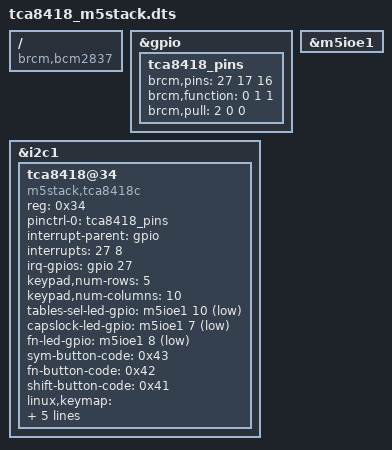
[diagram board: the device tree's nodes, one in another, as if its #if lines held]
/dts-v1/;
/plugin/;
// dtc -@ -I dts -O dtb -o m5stac_tca8418.dtbo  m5stac-tca8418.dts
/{
 
compatible = "brcm,bcm2837";
fragment@0 {
	target = <&gpio>;
	__overlay__ {
			tca8418_pins: tca8418_pins {
					brcm,pins = <27 17 16>;
					brcm,function = <0 1 1>;
					brcm,pull = <2 0 0>;
			};
	};
};
fragment@1 {
	target = <&m5ioe1>;
	__overlay__ {
		status = "okay";
	};
};
fragment@2 {
	target = <&i2c1>;
	__overlay__{
            tca8418@34 {
                compatible = "m5stack,tca8418c"; 
                reg = <0x34>;
                pinctrl-names = "default";
                pinctrl-0 = <&tca8418_pins>;
                interrupt-parent = <&gpio>;
                interrupts = <27 8>; /* Interrupt IO, low-level trigger */
                irq-gpios = <&gpio 27 0x00>;
                    
                keypad,num-rows = <5>;
                keypad,num-columns = <10>;

#if CONFIG_CARDPUTERO_V0_5
                tables-sel-led-gpio = <&m5ioe1 10 1>;
                capslock-led-gpio   = <&m5ioe1 7 1>;
                fn-led-gpio         = <&m5ioe1 8 1>;
                // tables-sel-led-mode    = <&m5ioe1 15>;
                // capslock-led-mode    = <&m5ioe1 16>;
                // fn-led-mode    = <&m5ioe1 17>;
#else
                tables-sel-led-gpio = <&m5ioe1 8 1>;
                capslock-led-gpio   = <&m5ioe1 7 1>;
#endif

                sym-button-code = <0x43>; 
                fn-button-code = <0x42>;  
                shift-button-code = <0x41>; 

                // switch-button-code = <73>; /* Switch button keycode */
                // interrupt-controller;
                /* row | column | key-code, for example: 04,08,0010 for the Q key */
                /* row | column | key-code, for example: 04,08,0010 => Q key */
                linux,keymap = <
                    0x04000001 /* row=0x04 col=0x00 keycode=0x0001  KEY_ESC        Esc */
                    0x0409000f /* row=0x04 col=0x09 keycode=0x000f  KEY_TAB        Tab */

                    0x04040002 /* row=0x04 col=0x04 keycode=0x0002  KEY_1          1 */
                    0x00000003 /* row=0x00 col=0x00 keycode=0x0003  KEY_2          2 */
                    0x00010004 /* row=0x00 col=0x01 keycode=0x0004  KEY_3          3 */
                    0x00020005 /* row=0x00 col=0x02 keycode=0x0005  KEY_4          4 */
                    0x00030006 /* row=0x00 col=0x03 keycode=0x0006  KEY_5          5 */
                    0x00040007 /* row=0x00 col=0x04 keycode=0x0007  KEY_6          6 */
                    0x00050008 /* row=0x00 col=0x05 keycode=0x0008  KEY_7          7 */
                    0x00060009 /* row=0x00 col=0x06 keycode=0x0009  KEY_8          8 */
                    0x0007000a /* row=0x00 col=0x07 keycode=0x000a  KEY_9          9 */
                    0x0008000b /* row=0x00 col=0x08 keycode=0x000b  KEY_0          0 */
                    0x0009000e /* row=0x00 col=0x09 keycode=0x000e  KEY_BACKSPACE  Backspace */

                    0x0403017f /* row=0x04 col=0x03 keycode=0x017f  KEY_CD  Sym function key */
                    0x01000010 /* row=0x01 col=0x00 keycode=0x0010  KEY_Q          Q */
                    0x01010011 /* row=0x01 col=0x01 keycode=0x0011  KEY_W          W */
                    0x01020012 /* row=0x01 col=0x02 keycode=0x0012  KEY_E          E */
                    0x01030013 /* row=0x01 col=0x03 keycode=0x0013  KEY_R          R */
                    0x01040014 /* row=0x01 col=0x04 keycode=0x0014  KEY_T          T */
                    0x01050015 /* row=0x01 col=0x05 keycode=0x0015  KEY_Y          Y */
                    0x01060016 /* row=0x01 col=0x06 keycode=0x0016  KEY_U          U */
                    0x01070017 /* row=0x01 col=0x07 keycode=0x0017  KEY_I          I */
                    0x01080018 /* row=0x01 col=0x08 keycode=0x0018  KEY_O          O */
                    0x01090019 /* row=0x01 col=0x09 keycode=0x0019  KEY_P          P */


                    0x0401002a /* row=0x04 col=0x01 keycode=0x002a  KEY_LEFTSHIFT    Left Shift */
                    0x0200001e /* row=0x02 col=0x00 keycode=0x001e  KEY_A          A */
                    0x0201001f /* row=0x02 col=0x01 keycode=0x001f  KEY_S          S */
                    0x02020020 /* row=0x02 col=0x02 keycode=0x0020  KEY_D          D */
                    0x02030021 /* row=0x02 col=0x03 keycode=0x0021  KEY_F          F */
                    0x02040022 /* row=0x02 col=0x04 keycode=0x0022  KEY_G          G */
                    0x02050023 /* row=0x02 col=0x05 keycode=0x0023  KEY_H          H */
                    0x02060024 /* row=0x02 col=0x06 keycode=0x0024  KEY_J          J */
                    0x02070025 /* row=0x02 col=0x07 keycode=0x0025  KEY_K          K */
                    0x02080026 /* row=0x02 col=0x08 keycode=0x0026  KEY_L          L */
                    0x0209001c /* row=0x02 col=0x09 keycode=0x001c  KEY_ENTER      Enter */

                    0x04020185 /* row=0x04 col=0x02 keycode=0x0185  KEY_DVD  Fn function key */
                    0x0300001d /* row=0x03 col=0x00 keycode=0x001d  KEY_LEFTCTRL   Left Ctrl */
                    0x03010038 /* row=0x03 col=0x01 keycode=0x0038  KEY_LEFTALT    Left Alt  */
                    0x0302002c /* row=0x03 col=0x02 keycode=0x002c  KEY_Z          Z */
                    0x0303002d /* row=0x03 col=0x03 keycode=0x002d  KEY_X          X */
                    0x0304002e /* row=0x03 col=0x04 keycode=0x002e  KEY_C          C */
                    0x0305002f /* row=0x03 col=0x05 keycode=0x002f  KEY_V          V */
                    0x03060030 /* row=0x03 col=0x06 keycode=0x0030  KEY_B          B */
                    0x03070031 /* row=0x03 col=0x07 keycode=0x0031  KEY_N          N */
                    0x03080032 /* row=0x03 col=0x08 keycode=0x0032  KEY_M          M */
                    0x03090039 /* row=0x03 col=0x09 keycode=0x0039  KEY_SPACE      Space */
                    >;
                /* row | column | key-code */
                linux,keymap1 = <
                    0x04000001 /* row=0x04 col=0x00 keycode=0x0001  KEY_ESC        Esc */
                    0x0409000f /* row=0x04 col=0x09 keycode=0x000f  KEY_TAB        Tab */


                    0x0404001a /* row=0x04 col=0x04 keycode=0x001a  KEY_LEFTBRACE          Left Brace */
                    0x0000001b /* row=0x00 col=0x00 keycode=0x001b  KEY_RIGHTBRACE         Right Brace */
                    0x00010027 /* row=0x00 col=0x01 keycode=0x0027  KEY_SEMICOLON          Semicolon */
                    0x00020028 /* row=0x00 col=0x02 keycode=0x0028  KEY_APOSTROPHE         Apostrophe */
                    0x00030029 /* row=0x00 col=0x03 keycode=0x0029  KEY_GRAVE              Grave */
                    0x0004002b /* row=0x00 col=0x04 keycode=0x002b  KEY_BACKSLASH          Backslash */
                    0x00050033 /* row=0x00 col=0x05 keycode=0x0033  KEY_COMMA              Comma */
                    0x00060034 /* row=0x00 col=0x06 keycode=0x0034  KEY_DOT                Dot */
                    0x00070035 /* row=0x00 col=0x07 keycode=0x0035  KEY_SLASH              Slash */
                    0x0008005e /* row=0x00 col=0x08 keycode=0x005e  KEY_MUHENKAN           Muhenkan */
                    0x0009000e /* row=0x00 col=0x09 keycode=0x000e  KEY_BACKSPACE    Backspace */

                    0x0403017f /* row=0x04 col=0x03 keycode=0x017f  KEY_CD  Sym function key */
                    0x01000037 /* row=0x01 col=0x00 keycode=0x0037  KEY_KPASTERISK         Keypad Asterisk */
                    0x01010045 /* row=0x01 col=0x01 keycode=0x0045  KEY_NUMLOCK            Num Lock */
                    0x01020046 /* row=0x01 col=0x02 keycode=0x0046  KEY_SCROLLLOCK         Scroll Lock */
                    0x01030047 /* row=0x01 col=0x03 keycode=0x0047  KEY_KP7                Keypad 7 */
                    0x01040048 /* row=0x01 col=0x04 keycode=0x0048  KEY_KP8                Keypad 8 */
                    0x01050049 /* row=0x01 col=0x05 keycode=0x0049  KEY_KP9                Keypad 9 */
                    0x0106004a /* row=0x01 col=0x06 keycode=0x004a  KEY_KPMINUS            Keypad Minus */
                    0x0107004b /* row=0x01 col=0x07 keycode=0x004b  KEY_KP4                Keypad 4 */
                    0x0108004c /* row=0x01 col=0x08 keycode=0x004c  KEY_KP5                Keypad 5 */
                    0x0109004d /* row=0x01 col=0x09 keycode=0x004d  KEY_KP6                Keypad 6 */


                    0x0401004e /* row=0x04 col=0x01 keycode=0x004e  KEY_KPPLUS             Keypad Plus */
                    0x0200004f /* row=0x02 col=0x00 keycode=0x004f  KEY_KP1                Keypad 1 */
                    0x02010050 /* row=0x02 col=0x01 keycode=0x0050  KEY_KP2                Keypad 2 */
                    0x02020051 /* row=0x02 col=0x02 keycode=0x0051  KEY_KP3                Keypad 3 */
                    0x02030000 /* row=0x02 col=0x03 keycode=0x0000  KEY_RESERVED     F disabled */
                    0x02040052 /* row=0x02 col=0x04 keycode=0x0052  KEY_KP0                Keypad 0 */
                    0x02050053 /* row=0x02 col=0x05 keycode=0x0053  KEY_KPDOT              Keypad Dot */
                    0x02060055 /* row=0x02 col=0x06 keycode=0x0055  KEY_ZENKAKUHANKAKU     Zenkaku/Hankaku */
                    0x02070056 /* row=0x02 col=0x07 keycode=0x0056  KEY_102ND              102nd */
                    0x02080059 /* row=0x02 col=0x08 keycode=0x0059  KEY_RO                 Ro */
                    0x0209001c /* row=0x02 col=0x09 keycode=0x001c  KEY_ENTER        Enter */

                    0x04020185 /* row=0x04 col=0x02 keycode=0x0185  KEY_DVD  Fn function key */
                    0x0300001d /* row=0x03 col=0x00 keycode=0x001d  KEY_LEFTCTRL   Left Ctrl */
                    0x03010038 /* row=0x03 col=0x01 keycode=0x0038  KEY_LEFTALT    Left Alt  */
                    0x03020000 /* row=0x03 col=0x02 keycode=0x0000  KEY_RESERVED     Z disabled */
                    0x03030000 /* row=0x03 col=0x03 keycode=0x0000  KEY_RESERVED     X disabled */
                    0x03040000 /* row=0x03 col=0x04 keycode=0x0000  KEY_RESERVED     C disabled */
                    0x0305005a /* row=0x03 col=0x05 keycode=0x005a  KEY_KATAKANA           Katakana */
                    0x0306005b /* row=0x03 col=0x06 keycode=0x005b  KEY_HIRAGANA           Hiragana */
                    0x0307005c /* row=0x03 col=0x07 keycode=0x005c  KEY_HENKAN             Henkan */
                    0x0308005d /* row=0x03 col=0x08 keycode=0x005d  KEY_KATAKANAHIRAGANA   Katakana/Hiragana */
                    0x03090039 /* row=0x03 col=0x09 keycode=0x0039  KEY_SPACE        Space */
                    >;
                linux,keymap2 = <
                    0x04000001 /* row=0x04 col=0x00 keycode=0x0001  KEY_ESC        Esc */
                    0x0409000f /* row=0x04 col=0x09 keycode=0x000f  KEY_TAB        Tab */


                    0x0404003b /* row=0x04 col=0x04 keycode=0x003b  KEY_F1           F1 */
                    0x0000003c /* row=0x00 col=0x00 keycode=0x003c  KEY_F2           F2 */
                    0x0001003d /* row=0x00 col=0x01 keycode=0x003d  KEY_F3           F3 */
                    0x0002003e /* row=0x00 col=0x02 keycode=0x003e  KEY_F4           F4 */
                    0x0003003f /* row=0x00 col=0x03 keycode=0x003f  KEY_F5           F5 */
                    0x00040040 /* row=0x00 col=0x04 keycode=0x0040  KEY_F6           F6 */
                    0x00050041 /* row=0x00 col=0x05 keycode=0x0041  KEY_F7           F7 */
                    0x00060042 /* row=0x00 col=0x06 keycode=0x0042  KEY_F8           F8 */
                    0x00070043 /* row=0x00 col=0x07 keycode=0x0043  KEY_F9           F9 */
                    0x00080044 /* row=0x00 col=0x08 keycode=0x0044  KEY_F10          F10 */
                    0x0009006f /* row=0x00 col=0x09 keycode=0x006f  KEY_DELETE       Delete */

                    0x0403017f /* row=0x04 col=0x03 keycode=0x017f  KEY_CD  Sym function key */
                    0x010000a4 /* row=0x01 col=0x00 keycode=0x00a4  KEY_PLAYPAUSE          Play/Pause */
                    0x010100a5 /* row=0x01 col=0x01 keycode=0x00a5  KEY_PREVIOUSSONG       Previous Song */
                    0x010200a3 /* row=0x01 col=0x02 keycode=0x00a3  KEY_NEXTSONG           Next Song */
                    0x01030013 /* row=0x01 col=0x03 keycode=0x0013  KEY_R          R */
                    0x01040014 /* row=0x01 col=0x04 keycode=0x0014  KEY_T          T */
                    0x01050015 /* row=0x01 col=0x05 keycode=0x0015  KEY_Y          Y */
                    0x010600e0 /* row=0x01 col=0x06 keycode=0x00e0  KEY_BRIGHTNESSDOWN     Brightness Down */
                    0x010700e1 /* row=0x01 col=0x07 keycode=0x00e1  KEY_BRIGHTNESSUP       Brightness Up */
                    0x01080057 /* row=0x01 col=0x08 keycode=0x0057  KEY_F11        F11 */
                    0x01090058 /* row=0x01 col=0x09 keycode=0x0058  KEY_F12        F12 */


                    0x0401002a /* row=0x04 col=0x01 keycode=0x002a  KEY_LEFTSHIFT          Left Shift */
                    0x02000071 /* row=0x02 col=0x00 keycode=0x0071  KEY_MUTE       MUTE */
                    0x02010072 /* row=0x02 col=0x01 keycode=0x0072  KEY_VOLUMEDOWN VOLUMEDOWN */
                    0x02020073 /* row=0x02 col=0x02 keycode=0x0073  KEY_VOLUMEUP   VOLUMEUP */
                    0x02030067 /* row=0x02 col=0x03 keycode=0x0067  KEY_UP          Up */
                    0x02040022 /* row=0x02 col=0x04 keycode=0x0022  KEY_G          G */
                    0x0205008a /* row=0x02 col=0x05 keycode=0x008a  KEY_HELP        Help */
                    0x02060063 /* row=0x02 col=0x06 keycode=0x0063  KEY_SYSRQ       SysRq */
                    0x02070066 /* row=0x02 col=0x07 keycode=0x0066  KEY_HOME        Home */
                    0x02080068 /* row=0x02 col=0x08 keycode=0x0068  KEY_PAGEUP      Page Up */
                    0x0209001c /* row=0x02 col=0x09 keycode=0x001c  KEY_ENTER      Enter */

                    0x04020185 /* row=0x04 col=0x02 keycode=0x0185  KEY_DVD  Fn function key */
                    0x0300001d /* row=0x03 col=0x00 keycode=0x001d  KEY_LEFTCTRL   Left Ctrl */
                    0x03010038 /* row=0x03 col=0x01 keycode=0x0038  KEY_LEFTALT    Left Alt  */
                    0x03020069 /* row=0x03 col=0x02 keycode=0x0069  KEY_LEFT        Left */
                    0x0303006c /* row=0x03 col=0x03 keycode=0x006c  KEY_DOWN        Down */
                    0x0304006a /* row=0x03 col=0x04 keycode=0x006a  KEY_RIGHT       Right */
                    0x0305002f /* row=0x03 col=0x05 keycode=0x002f  KEY_V          V */
                    0x0306006e /* row=0x03 col=0x06 keycode=0x006e  KEY_INSERT      Insert */
                    0x0307006b /* row=0x03 col=0x07 keycode=0x006b  KEY_END         End */
                    0x0308006d /* row=0x03 col=0x08 keycode=0x006d  KEY_PAGEDOWN    Page Down */
                    0x03090039 /* row=0x03 col=0x09 keycode=0x0039  KEY_SPACE      Space */
                    >;
            };
        };
	};
 
};

/*

*/
